# PY32F030xx register map
Vendor: Puya; Series: PY32F0; File version: 1.0.0
CPU: CM0+ r0p1, little endian, no MPU, no FPU, 4 interrupt priority bits
Registers are 32-bit, read-write, reset 0x0 unless marked. A register's access mark holds for its fields unless they carry their own. Offsets are from the block's base; [hi:lo] are bit positions.

## RCC — Reset and clock control
Base 0x40021000
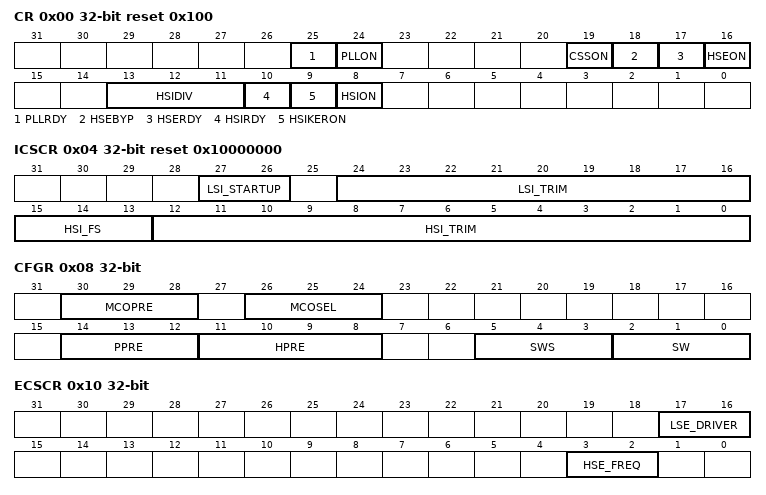
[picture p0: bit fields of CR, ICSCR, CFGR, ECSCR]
0x00 CR reset 0x100 — Clock control register
  [25] PLLRDY — PLL clock ready flag
  [24] PLLON — PLL enable
  [19] CSSON — Clock security systemenable
  [18] HSEBYP — HSE crystal oscillatorbypass
  [17] HSERDY — HSE clock ready flag
  [16] HSEON — HSE clock enable
  [13:11] HSIDIV — HSI16 clock divisionfactor
    1=0; 2=1; 4=2
  [10] HSIRDY — HSI16 clock ready flag
  [9] HSIKERON — HSI16 always enable for peripheralkernels
  [8] HSION — HSI16 clock enable
0x04 ICSCR reset 0x10000000 — Internal clock sources calibrationregister
  [27:26] LSI_STARTUP — LSI startup time
    1=0; 2=1
  [24:16] LSI_TRIM — LSI clock trimming
    1=0; 2=1; 4=2; 8=3; 16=4; 32=5; 64=6; 128=7; 0x100=8
  [15:13] HSI_FS — HSI frequency selection
    4=Freq24MHz (24 MHz HSI clock)
  [12:0] HSI_TRIM — HSI clock trimming
    1=0; 2=1; 4=2; 8=3; 16=4; 32=5; 64=6; 128=7; 0x100=8; 0x200=9; 0x400=10; 0x800=11; 0x1000=12
0x08 CFGR — Clock configuration register
  [30:28] MCOPRE — Microcontroller clock outputprescaler
    1=0; 2=1; 4=2
  [26:24] MCOSEL — Microcontroller clockoutput
    1=0; 2=1; 4=2
  [14:12] PPRE — APB prescaler
    1=0; 2=1; 4=2
  [11:8] HPRE — AHB prescaler
    1=0; 2=1; 4=2; 8=3
  [5:3] SWS ro — System clock switch status
    0=HSI (HSI used as system clock); 1=0; 1=HSE (HSE used as system clock); 2=1; 2=PLL (PLL used as system clock); 3=LSI (LSI used as system clock); 4=2; 4=LSE (LSE used as system clock)
  [2:0] SW — System clock switch
    1=0; 2=1; 4=2
0x0C PLLCFGR — PLL configuration register
  [0] PLLSRC — PLL clock source selection
    0=HSI (HSI source clock selected); 0=NONE (No clock sent to PLL); 1=HSE (HSE source clock selected)
0x10 ECSCR — External clock source control register
  [17:16] LSE_DRIVER — LSE clock driver selection
    1=0; 2=1
  [3:2] HSE_FREQ — HSE clock freqency selection
    1=0; 2=1
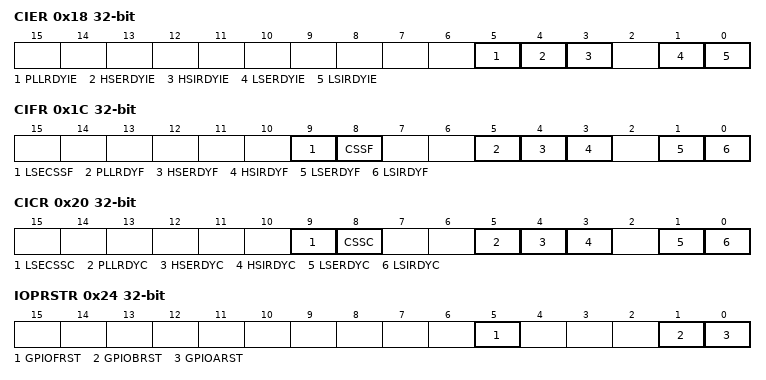
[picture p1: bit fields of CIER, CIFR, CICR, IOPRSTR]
0x18 CIER — Clock interrupt enableregister
  [5] PLLRDYIE — PLL ready interrupt enable
  [4] HSERDYIE — HSE ready interrupt enable
  [3] HSIRDYIE — HSI ready interrupt enable
  [1] LSERDYIE — LSE ready interrupt enable
  [0] LSIRDYIE — LSI ready interrupt enable
0x1C CIFR ro — Clock interrupt flag register
  [9] LSECSSF — LSE clock secure system interrupt flag
  [8] CSSF — HSE clock secure system interrupt flag
  [5] PLLRDYF — PLL ready interrupt flag
  [4] HSERDYF — HSE ready interrupt flag
  [3] HSIRDYF — HSI ready interrupt flag
  [1] LSERDYF — LSE ready interrupt flag
  [0] LSIRDYF — LSI ready interrupt flag
0x20 CICR wo — Clock interrupt clear register
  [9] LSECSSC — LSE clock secure system interrupt flag clear
  [8] CSSC — clock secure system interrupt flag clear
  [5] PLLRDYC — PLL ready interrupt clear
  [4] HSERDYC — HSE ready interrupt clear
  [3] HSIRDYC — HSI ready interrupt clear
  [1] LSERDYC — LSE ready interrupt clear
  [0] LSIRDYC — LSI ready interrupt clear
0x24 IOPRSTR — GPIO reset register
  [5] GPIOFRST — I/O port F reset
  [1] GPIOBRST — I/O port B reset
  [0] GPIOARST — I/O port A reset
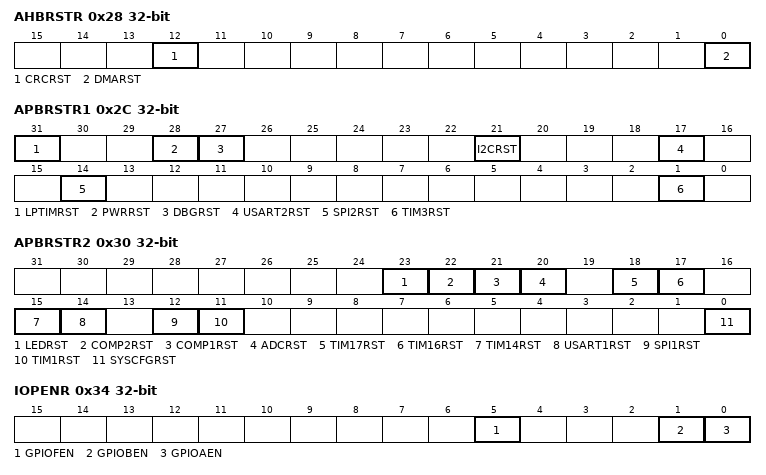
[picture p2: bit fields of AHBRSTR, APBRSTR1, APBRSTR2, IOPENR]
0x28 AHBRSTR — AHB peripheral reset register
  [12] CRCRST — CRC reset
  [0] DMARST — DMA reset
0x2C APBRSTR1 — APB peripheral reset register1
  [31] LPTIMRST — Low Power Timer reset
  [28] PWRRST — Power interface reset
  [27] DBGRST — Debug support reset
  [21] I2CRST — I2C reset
  [17] USART2RST — USART2 reset
  [14] SPI2RST — SPI2 reset
  [1] TIM3RST — TIM3 timer reset
0x30 APBRSTR2 — APB peripheral reset register2
  [23] LEDRST — LED reset
  [22] COMP2RST — COMP2 reset
  [21] COMP1RST — COMP1 reset
  [20] ADCRST — ADC reset
  [18] TIM17RST — TIM17 timer reset
  [17] TIM16RST — TIM16 timer reset
  [15] TIM14RST — TIM14 timer reset
  [14] USART1RST — USART1 reset
  [12] SPI1RST — SPI1 reset
  [11] TIM1RST — TIM1 timer reset
  [0] SYSCFGRST — SYSCFG and COMPreset
0x34 IOPENR — GPIO clock enable register
  [5] GPIOFEN — I/O port F clock enable
  [1] GPIOBEN — I/O port B clock enable
  [0] GPIOAEN — I/O port A clock enable
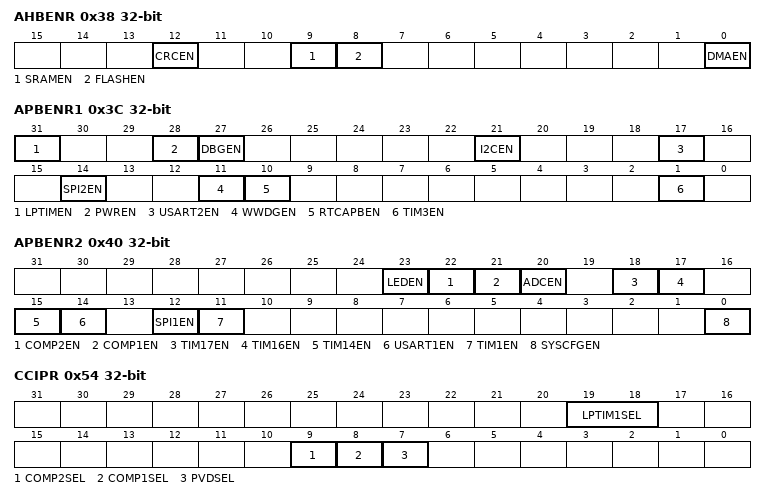
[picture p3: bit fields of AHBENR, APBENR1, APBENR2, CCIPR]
0x38 AHBENR — AHB peripheral clock enableregister
  [12] CRCEN — CRC clock enable
  [9] SRAMEN — SRAM memory interface clockenable
  [8] FLASHEN — Flash memory interface clockenable
  [0] DMAEN — DMA clock enable
0x3C APBENR1 — APB peripheral clock enable register1
  [31] LPTIMEN — LPTIM clock enable
  [28] PWREN — Power interface clockenable
  [27] DBGEN — Debug support clock enable
  [21] I2CEN — I2C clock enable
  [17] USART2EN — USART2 clock enable
  [14] SPI2EN — SPI2 clock enable
  [11] WWDGEN — WWDG clock enable
  [10] RTCAPBEN — RTC APB clock enable
  [1] TIM3EN — TIM3 timer clock enable
0x40 APBENR2 — APB peripheral clock enable register2
  [23] LEDEN — LED clock enable
  [22] COMP2EN — COMP2 clock enable
  [21] COMP1EN — COMP1 clock enable
  [20] ADCEN — ADC clock enable
  [18] TIM17EN — TIM16 timer clock enable
  [17] TIM16EN — TIM16 timer clock enable
  [15] TIM14EN — TIM14 timer clock enable
  [14] USART1EN — USART1 clock enable
  [12] SPI1EN — SPI1 clock enable
  [11] TIM1EN — TIM1 timer clock enable
  [0] SYSCFGEN — SYSCFG, COMP and VREFBUF clockenable
0x54 CCIPR — Peripherals independent clock configurationregister
  [19:18] LPTIM1SEL — LPTIM1 clock sourceselection
  [9] COMP2SEL — COMP2 clock sourceselection
  [8] COMP1SEL — COMP1 clock sourceselection
  [7] PVDSEL — PVD detect clock sourceselection
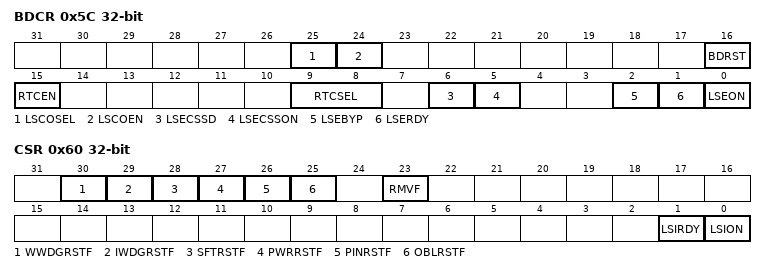
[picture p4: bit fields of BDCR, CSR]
0x5C BDCR — RTC domain control register
  [25] LSCOSEL — Low-speed clock outputselection
  [24] LSCOEN — Low-speed clock output (LSCO)enable
  [16] BDRST — RTC domain software reset
  [15] RTCEN — RTC clock source enable
  [9:8] RTCSEL — RTC clock source selection
    1=0; 2=1
  [6] LSECSSD — LSE CSS detect
  [5] LSECSSON — LSE CSS enable
  [2] LSEBYP — LSE oscillator bypass
  [1] LSERDY — LSE oscillator ready
  [0] LSEON — LSE oscillator enable
0x60 CSR — Control/status register
  [30] WWDGRSTF — Window watchdog reset flag
  [29] IWDGRSTF — Independent window watchdog resetflag
  [28] SFTRSTF — Software reset flag
  [27] PWRRSTF — BOR or POR/PDR flag
  [26] PINRSTF — Pin reset flag
  [25] OBLRSTF — Option byte loader resetflag
  [23] RMVF — Remove reset flags
  [1] LSIRDY — LSI oscillator ready
  [0] LSION — LSI oscillator enable
